# 3061MNNIKA register map
File version: 1.0
Registers are 32-bit, access per field, reset 0x0 unless marked. A register's access mark holds for its fields unless they carry their own. Offsets are from the block's base; [hi:lo] are bit positions; {n}, {i} and the like mark numbered series.

## GPIO0 — GPIO peripheral interface
Base 0x14500000
Same registers: GPIO1 0x14501000, GPIO2 0x14502000, GPIO3 0x14503000, GPIO4 0x14504000, GPIO5 0x14505000
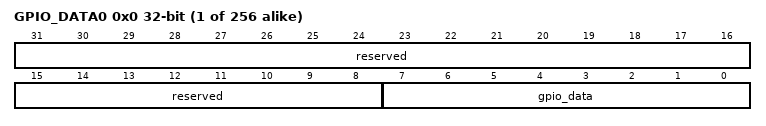
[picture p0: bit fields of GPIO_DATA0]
{0x0+4i} GPIO_DATA{i} (i=0..255) — GPIO_DATA为GPIO 数据寄存器，用来对输入或输出数据进行缓存。
  [31:8] reserved ro — 保留。
  [7:0] gpio_data rw — 当GPIO配置为输入模式时，为GPIO输入数据；当GPIO配置为输出模式时，为输出数据。各比特均可独立控制。与GPIO_DIR配合使用。
0x400 GPIO_DIR 8-bit rw — GPIO方向控制寄存器。用来配置GPIO方向。
  [7:0] gpio_dir — GPIO方向控制寄存器。bit[7:0]分别对应GPIO_DATA bit[7:0]，各比特可独立控制。 0：输入； 1：输出。
0x404 GPIO_IS 8-bit rw — GPIO中断触发寄存器。用来配置GPIO触发电平方式。
  [7:0] gpio_is — GPIO中断触发控制寄存器，bit[7:0]分别对应GPIO_DATA bit[7:0]，各比特独立控制。 0：边沿触发中断； 1：电平触发中断。
0x408 GPIO_IBE 8-bit rw — GPIO双沿触发中断寄存器。用来配置GPIO沿触发方式。
  [7:0] gpio_ibe — GPIO中断沿触发控制寄存器，bit[7:0]分别对应GPIO_DATA bit[7:0]，各比特独立控制。 0：单边沿触发中断，具体是上升沿还是下降沿触发由GPIO_IEV控制； 1：双边触发中断。
0x40C GPIO_IEV 8-bit rw — GPIO触发中断条件寄存器。用来配置GPIO触发中断条件。
  [7:0] gpio_iev — GPIO触发中断条件寄存器，bit[7:0]分别对应GPIO_DATA[7:0]，各比特独立控制。 0：下降沿或低电平触发中断，具体由GPIO_IS控制； 1：上升沿或高电平触发中断。
0x410 GPIO_IE 8-bit rw — GPIO中断屏蔽寄存器。用来屏蔽GPIO中断。
  [7:0] gpio_ie — GPIO中断屏蔽寄存器，bit[7:0]分别对应GPIO_DATA bit[7:0]，各比特独立控制。 0：屏蔽中断； 1：不屏蔽中断。
0x414 GPIO_RIS 8-bit ro — GPIO原始中断状态寄存器。用来查询GPIO原始中断状态。
  [7:0] gpio_ris — GPIO原始中断寄存器，bit[7:0]分别对应GPIO_DATA bit[7:0]，指示未屏蔽的中断状态。该状态不受GPIO_IE寄存器屏蔽控制。 0：未发生中断； 1：已发生中断。
0x418 GPIO_MIS 8-bit ro — GPIO屏蔽状态中断寄存器。用来查询GPIO屏蔽后的中断状态。对所有位进行或操作得到中断输出gpio_int。
  [7:0] gpio_mis — GPIO屏蔽后中断寄存器，bit[7:0]分别对应GPIO_DATA bit[7:0]，指示经屏蔽后的中断状态。该状态受GPIO_IE寄存器屏蔽控制。 0：中断无效； 1：中断有效。
0x41C GPIO_IC 8-bit rw — GPIO中断清除寄存器。用来清除GPIO产生的中断，同时清除GPIO_RIS寄存器和GPIO_MIS寄存器。
  [7:0] gpio_ic write-1-clears — GPIO中断清除寄存器，bit[7:0]分别对应GPIO_DATA bit[7:0]，各比特可独立控制。 0：无影响； 1：清除中断。

## IOCMG_AON — IOCMG_AON peripheral interface
Base 0x147F0000
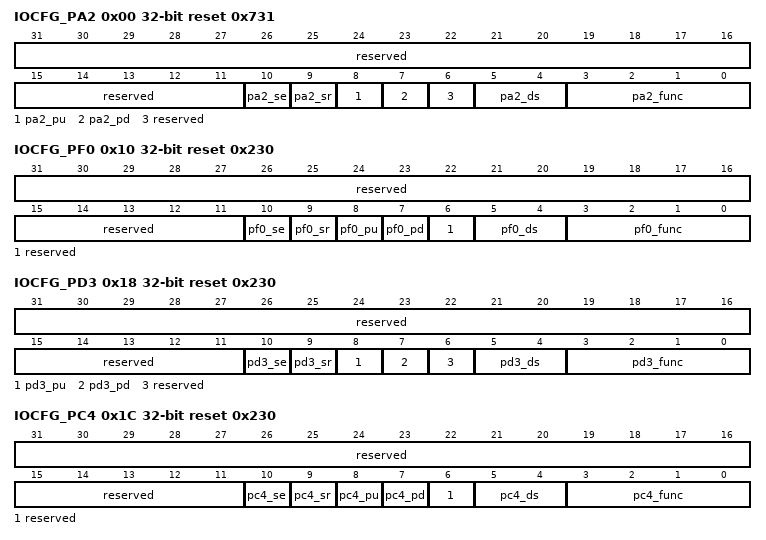
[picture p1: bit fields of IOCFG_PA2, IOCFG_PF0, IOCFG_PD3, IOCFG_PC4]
0x00 IOCFG_PA2 reset 0x731 — PA2管脚控制寄存器。
  [31:11] reserved ro — 保留。
  [10] pa2_se rw — 管脚施密特输入控制： 0x0：关闭； 0x1：打开。
  [9] pa2_sr rw — 管脚电平转换速率控制： 0x0：快沿输出； 0x1：慢沿输出。
  [8] pa2_pu rw — 管脚上拉控制： 0x0：关闭； 0x1：打开。
  [7] pa2_pd rw — 管脚下拉控制： 0x0：关闭； 0x1：打开。
  [6] reserved ro — 保留。
  [5:4] pa2_ds rw — 管脚驱动能力选择（档位越高，驱动能力越大）： 0x0：IO2档位4； 0x1：IO2档位3； 0x2：IO2档位2； 0x3：IO2档位1；
  [3:0] pa2_func rw — 管脚复用功能选择: 具体复用功能请参考《数据手册》。
0x10 IOCFG_PF0 reset 0x230 — PF0管脚控制寄存器。
  [31:11] reserved ro — 保留。
  [10] pf0_se rw — 管脚施密特输入控制： 0x0：关闭； 0x1：打开。
  [9] pf0_sr rw — 管脚电平转换速率控制： 0x0：快沿输出； 0x1：慢沿输出。
  [8] pf0_pu rw — 管脚上拉控制： 0x0：关闭； 0x1：打开。
  [7] pf0_pd rw — 管脚下拉控制： 0x0：关闭； 0x1：打开。
  [6] reserved ro — 保留。
  [5:4] pf0_ds rw — 管脚驱动能力选择（档位越高，驱动能力越大）： 0x0：IO2档位4； 0x1：IO2档位3； 0x2：IO2档位2； 0x3：IO2档位1；
  [3:0] pf0_func rw — 管脚复用功能选择: 具体复用功能请参考《数据手册》。
0x18 IOCFG_PD3 reset 0x230 — PD3管脚控制寄存器。
  [31:11] reserved ro — 保留。
  [10] pd3_se rw — 管脚施密特输入控制： 0x0：关闭； 0x1：打开。
  [9] pd3_sr rw — 管脚电平转换速率控制： 0x0：快沿输出； 0x1：慢沿输出。
  [8] pd3_pu rw — 管脚上拉控制： 0x0：关闭； 0x1：打开。
  [7] pd3_pd rw — 管脚下拉控制： 0x0：关闭； 0x1：打开。
  [6] reserved ro — 保留。
  [5:4] pd3_ds rw — 管脚驱动能力选择（档位越高，驱动能力越大）： 0x0：IO2档位4； 0x1：IO2档位3； 0x2：IO2档位2； 0x3：IO2档位1；
  [3:0] pd3_func rw — 管脚复用功能选择: 具体复用功能请参考《数据手册》。
0x1C IOCFG_PC4 reset 0x230 — PC4管脚控制寄存器。
  [31:11] reserved ro — 保留。
  [10] pc4_se rw — 管脚施密特输入控制： 0x0：关闭； 0x1：打开。
  [9] pc4_sr rw — 管脚电平转换速率控制： 0x0：快沿输出； 0x1：慢沿输出。
  [8] pc4_pu rw — 管脚上拉控制： 0x0：关闭； 0x1：打开。
  [7] pc4_pd rw — 管脚下拉控制： 0x0：关闭； 0x1：打开。
  [6] reserved ro — 保留。
  [5:4] pc4_ds rw — 管脚驱动能力选择（档位越高，驱动能力越大）： 0x0：IO2档位4； 0x1：IO2档位3； 0x2：IO2档位2； 0x3：IO2档位1；
  [3:0] pc4_func rw — 管脚复用功能选择: 具体复用功能请参考《数据手册》。

## IWDG — IWDG peripheral interface
Base 0x14401000
0x00 IWDG_LOAD 8-bit rw reset 0xFF — 计数初值寄存器。
  [7:0] iwdg_load — 计数初值。
0x04 IWDG_VALUE 8-bit ro reset 0xFF — 计数器当前值寄存器。
  [7:0] iwdg_value — WatchDog计数器当前值，读出值延后于实际计数器的当前值约50us。
0x08 IWDG_WINDOW 8-bit rw reset 0xFF — 窗口值寄存器。
  [7:0] iwdg_window — 窗口值，禁止大于计数初值寄存器，否则会产生预期之外的动作。 禁止配置窗口值小于等于4，否则喂狗指令不会及时生效，会导致IWDG复位。
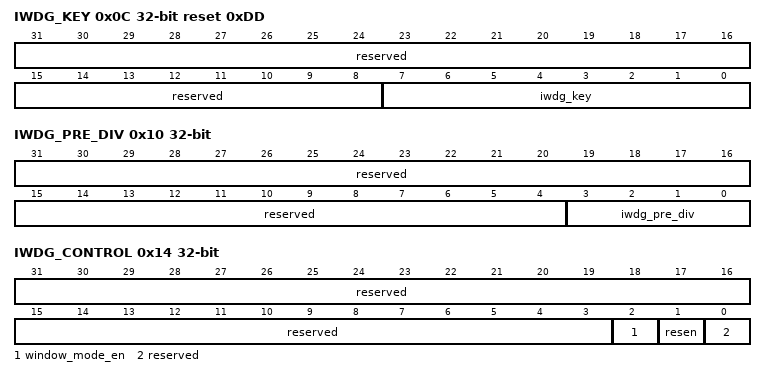
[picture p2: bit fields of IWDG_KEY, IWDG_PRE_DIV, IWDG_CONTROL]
0x0C IWDG_KEY reset 0xDD — 指令字寄存器。
  [31:8] reserved ro — 保留。
  [7:0] iwdg_key rw — 对该寄存器写入0xAA使WatchDog从寄存器IWDG_LOAD中重新载入初值计数（喂狗），并可清除WatchDog的中断。 向该寄存器写入0x55，可打开所有可写寄存器的写权限； 向该寄存器写入其他值，关闭所有可写寄存器写权限；本寄存器始终写有效； 向该寄存器写入0xCC，可开启IWDG； 向该寄存器写入0xDD，可关闭IWDG。
0x10 IWDG_PRE_DIV — 预分频寄存器。
  [31:4] reserved ro — 保留。
  [3:0] iwdg_pre_div rw — 工作时钟的2的幂次分频。 0x0：不分频； 0x1：2分频； 0x2：4分频： … 0x8：256分频； 其他：保留。 最多支持256分频。 配置大于最大分频值的值，按最大分频值进行分频。
0x14 IWDG_CONTROL — 控制寄存器。
  [31:3] reserved ro — 保留。
  [2] window_mode_en rw — WatchDog窗口模式使能。 0：禁止； 1：使能。 当禁止窗口模式时，无需设置iwdg_window，中断固定在iwdg_load/2处产生，此时在任意时刻喂狗均不会触发复位信号，复位信号只有在计数值为0且未清除中断时才会产生。 当使能窗口模式时，iwdg_window值生效，中断在计数器值等于窗口值时产生，在窗口值之外喂狗会产生复位信号，在计数为0且未清除中断时也会产生复位信号。
  [1] resen rw — WatchDog复位信号输出使能。 0：禁止； 1：使能。
  [0] reserved ro — 保留。
